# ATmega1284P device description
Architecture: AVR8; Family: megaAVR
Registers are 8-bit, access not given, no defined reset value unless marked. A register's access mark holds for its fields unless they carry their own. Offsets are from the block's base; [hi:lo] are bit positions.

## PORTA — I/O Port
Instances: PORTA 0x00
0x20 PINA — Port A Input Pins
0x21 DDRA — Port A Data Direction Register
0x22 PORTA — Port A Data Register

## PORTB — I/O Port
Instances: PORTB 0x00
0x23 PINB — Port B Input Pins
0x24 DDRB — Port B Data Direction Register
0x25 PORTB — Port B Data Register

## PORTC — I/O Port
Instances: PORTC 0x00
0x26 PINC — Port C Input Pins
0x27 DDRC — Port C Data Direction Register
0x28 PORTC — Port C Data Register

## PORTD — I/O Port
Instances: PORTD 0x00
0x29 PIND — Port D Input Pins
0x2A DDRD — Port D Data Direction Register
0x2B PORTD — Port D Data Register

## TC0 (TC8 module) — Timer/Counter, 8-bit
Instances: TC0 0x00
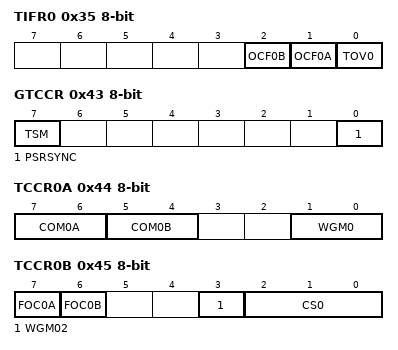
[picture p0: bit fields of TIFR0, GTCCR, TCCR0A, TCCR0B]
0x35 TIFR0 — Timer/Counter0 Interrupt Flag register
  [2] OCF0B — Timer/Counter0 Output Compare Flag 0B
  [1] OCF0A — Timer/Counter0 Output Compare Flag 0A
  [0] TOV0 — Timer/Counter0 Overflow Flag
0x43 GTCCR — General Timer/Counter Control Register
  [7] TSM — Timer/Counter Synchronization Mode
  [0] PSRSYNC — Prescaler Reset Timer/Counter1 and Timer/Counter0
0x44 TCCR0A — Timer/Counter Control Register A
  [7:6] COM0A — Compare Output Mode, Phase Correct PWM Mode
  [5:4] COM0B — Compare Output Mode, Fast PWm
  [1:0] WGM0 — Waveform Generation Mode
0x45 TCCR0B — Timer/Counter Control Register B
  [7] FOC0A — Force Output Compare A
  [6] FOC0B — Force Output Compare B
  [3] WGM02
  [2:0] CS0 — Clock Select
    0=No Clock Source (Stopped); 1=Running, No Prescaling; 2=Running, CLK/8; 3=Running, CLK/64; 4=Running, CLK/256; 5=Running, CLK/1024; 6=Running, ExtClk Tx Falling Edge; 7=Running, ExtClk Tx Rising Edge
0x46 TCNT0 — Timer/Counter0
  [7:0] TCNT0 — Timer/Counter0 bits
0x47 OCR0A — Timer/Counter0 Output Compare Register A
  [7:0] OCR0A — Timer/Counter0 Output Compare A bits
0x48 OCR0B — Timer/Counter0 Output Compare Register B
  [7:0] OCR0B — Timer/Counter0 Output Compare B bits
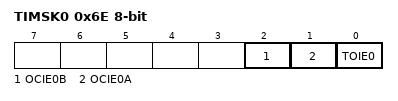
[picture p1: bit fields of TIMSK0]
0x6E TIMSK0 — Timer/Counter0 Interrupt Mask Register
  [2] OCIE0B — Timer/Counter0 Output Compare Match B Interrupt Enable
  [1] OCIE0A — Timer/Counter0 Output Compare Match A Interrupt Enable
  [0] TOIE0 — Timer/Counter0 Overflow Interrupt Enable

## TC1 (TC16 module) — Timer/Counter, 16-bit
Instances: TC1 0x00
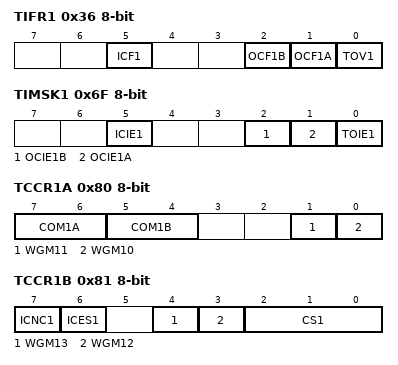
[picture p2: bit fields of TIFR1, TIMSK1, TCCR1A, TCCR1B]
0x36 TIFR1 — Timer/Counter Interrupt Flag register
  [5] ICF1 — Timer/Counter1 Input Capture Flag
  [2] OCF1B — Timer/Counter1 Output Compare B Match Flag
  [1] OCF1A — Timer/Counter1 Output Compare A Match Flag
  [0] TOV1 — Timer/Counter1 Overflow Flag
0x6F TIMSK1 — Timer/Counter1 Interrupt Mask Register
  [5] ICIE1 — Timer/Counter1 Input Capture Interrupt Enable
  [2] OCIE1B — Timer/Counter1 Output Compare B Match Interrupt Enable
  [1] OCIE1A — Timer/Counter1 Output Compare A Match Interrupt Enable
  [0] TOIE1 — Timer/Counter1 Overflow Interrupt Enable
0x80 TCCR1A — Timer/Counter1 Control Register A
  [7:6] COM1A — Compare Output Mode 1A, bits
  [5:4] COM1B — Compare Output Mode 1B, bits
  [1] WGM11 — Waveform Generation Mode
  [0] WGM10 — Waveform Generation Mode
0x81 TCCR1B — Timer/Counter1 Control Register B
  [7] ICNC1 — Input Capture 1 Noise Canceler
  [6] ICES1 — Input Capture 1 Edge Select
  [4] WGM13 (bit 2 of the value upward) — Waveform Generation Mode
  [3] WGM12 (bit 2 of the value upward) — Waveform Generation Mode
  [2:0] CS1 — Clock Select1 bits
    0=No Clock Source (Stopped); 1=Running, No Prescaling; 2=Running, CLK/8; 3=Running, CLK/64; 4=Running, CLK/256; 5=Running, CLK/1024; 6=Running, ExtClk Tx Falling Edge; 7=Running, ExtClk Tx Rising Edge
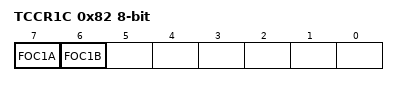
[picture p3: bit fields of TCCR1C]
0x82 TCCR1C — Timer/Counter1 Control Register C
  [7] FOC1A — Force Output Compare for Channel A
  [6] FOC1B — Force Output Compare for Channel B
0x84 TCNT1 16-bit — Timer/Counter1 Bytes
  [15:0] TCNT1 — Timer/Counter1 bits
0x86 ICR1 16-bit — Timer/Counter1 Input Capture Register Bytes
  [15:0] ICR1 — Timer/Counter1 Input Capture bits
0x88 OCR1A 16-bit — Timer/Counter1 Output Compare Register A Bytes
  [15:0] OCR1A — Timer/Counter1 Output Compare A bits
0x8A OCR1B 16-bit — Timer/Counter1 Output Compare Register B Bytes
  [15:0] OCR1B — Timer/Counter1 Output Compare B bits
